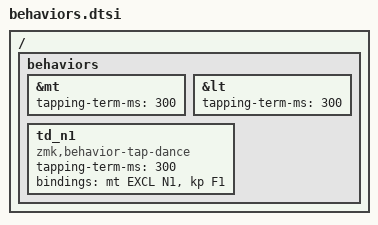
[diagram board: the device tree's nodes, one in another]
#include <dt-bindings/zmk/keys.h>

/ {
    behaviors {
        &mt {
            tapping-term-ms = <300>; // This is the value already set by default
        };
        
        &lt {
            tapping-term-ms = <300>; // This is the value already set by default
        };

        td_n1: td_n1 {
            compatible = "zmk,behavior-tap-dance";
            #binding-cells = <0>;
            tapping-term-ms = <300>;
            bindings = <&mt EXCL N1>, <&kp F1>;
        };
    };
};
